# NUC123AN_v1 register map
File version: 1.0
NUC123AN_v1 SVD file
Registers are 32-bit, read-write, reset 0x0 unless marked. A register's access mark holds for its fields unless they carry their own. Offsets are from the block's base; lines under a group give offsets from that group; [hi:lo] are bit positions; {n}, {i} and the like mark numbered series; 'fields as' and 'values as' point back to an identical list; <NAME> marks a mode.

## Memory map
0x40004000 WDT size 0x8 — WDT Register Map
0x40004100 WWDT size 0x10 — WWDT Register Map
0x40010000 TMR01 blocks up to offset 0x3C — TIMER Register Map
0x40020000 I2C0 blocks up to offset 0x44 — I2C Register Map
0x40030000 SPI0 blocks up to offset 0x48 — SPI Register Map
0x40034000 SPI1 blocks up to offset 0x48 — SPI Register Map
0x40040000 PWMA blocks up to offset 0xD4 — PWM Register Map
0x40050000 UART0 size 0x34 — UART Register Map
0x40060000 USB blocks up to offset 0x580 — USB Register Map
0x400E0000 ADC blocks up to offset 0x44 — ADC Register Map
0x40100000 PS2 size 0x20 — PS2 Register Map
0x40110000 TMR23 blocks up to offset 0x3C — TIMER Register Map
0x40120000 I2C1 blocks up to offset 0x44 — I2C Register Map
0x40130000 SPI2 blocks up to offset 0x48 — SPI Register Map
0x40150000 UART1 size 0x34 — UART Register Map
0x401A0000 I2S size 0x18 — I2S Register Map
0x50000000 GCR blocks up to offset 0x104 — GCR Register Map
0x50000200 CLK blocks up to offset 0x30 — CLK Register Map
0x50000300 INT size 0x88 — INT Register Map
0x50004000 GP blocks up to offset 0x350 — GP Register Map
0x50008000 PDMA_ch0 blocks up to offset 0x84 — PDMA Register Map
0x50008100 PDMA_ch1 blocks up to offset 0x84 — PDMA Register Map
0x50008200 PDMA_ch2 blocks up to offset 0x84 — PDMA Register Map
0x50008300 PDMA_ch3 blocks up to offset 0x84 — PDMA Register Map
0x50008400 PDMA_ch4 blocks up to offset 0x84 — PDMA Register Map
0x50008500 PDMA_ch5 blocks up to offset 0x84 — PDMA Register Map
0x50008E00 CRC blocks up to offset 0x8C — PDMA Register Map
0x50008F00 DMA_GCR size 0x14 — PDMA Register Map
0x5000C000 FMC size 0x1C — FMC Register Map
0xE000E000 SCS blocks up to offset 0xD24 — SCS Register Map

## FMC — FMC Register Map
Base 0x5000C000
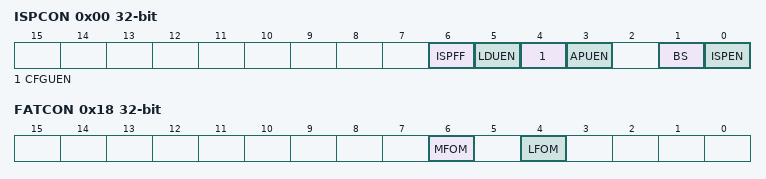
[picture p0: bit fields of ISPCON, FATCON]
0x00 ISPCON — ISP Control Register
  [6] ISPFF — ISP Fail Flag (Write-protection Bit). This bit is set by hardware when a triggered ISP meets any of the following conditions: (1) APROM writes to itself if APUEN is set to 0. (2) LDROM writes to itself if LDUEN is set to 0. (3) CONFIG is erased/programmed if CFGUEN is set to 0. (4) Destination address is illegal, such as over an available range. Write 1 to clear.
  [5] LDUEN — LDROM Update Enable (Write-protection Bit). LDROM update enable bit.
    0=LDROM cannot be updated; 1=LDROM can be updated
  [4] CFGUEN — Enable Config-bits Update by ISP (Write-protection Bit)
    0=ISP Disabled to update config-bits; 1=ISP Enabled to update config-bits
  [3] APUEN — APROM Update Enable (Write-protection Bit)
    0=APROM cannot be updated when the chip runs in APROM; 1=APROM can be updated when the chip runs in APROM
  [1] BS — Boot Select (Write-protection Bit). Set/clear this bit to select next booting from LDROM/APROM, respectively. This bit also functions as chip booting status flag, which can be used to check where chip booted from. This bit is initiated with the inversed value of CBS in Config0 after any reset is happened except CPU reset (RSTS_CPU is 1) or system reset (RSTS_SYS) is happened
    0=Boot from APROM; 1=Boot from LDROM
  [0] ISPEN — ISP Enable (Write-protection Bit). ISP function enable bit. Set this bit to enable ISP function.
    0=ISP function Disabled; 1=ISP function Enabled
0x04 ISPADR — ISP Address Register
  [31:0] ISPADR — ISP Address. The NuMicro( NUC123 Series is equipped with an embedded flash, and it supports word program only. ISPADR[1:0] must be kept 00b for ISP operation.
0x08 ISPDAT — ISP Data Register
  [31:0] ISPDAT — ISP Data. Write data to this register before ISP program operation. Read data from this register after ISP read operation.
0x0C ISPCMD — ISP Command Register
  [5:0] ISPCMD — ISP Command
0x10 ISPTRG — ISP Trigger Control Register
  [0] ISPGO — ISP Start Trigger. Write 1 to start ISP operation and this bit will be cleared to 0 by hardware automatically when ISP operation is finished.
    0=ISP operation is finished; 1=ISP is progressed
0x14 DFBADR ro reset not defined — Data Flash Start Address
  [31:0] DFBADR — Data Flash Base Address. This register indicates data flash start address. It is a read only register. When DFVSEN is set to 0, the data flash is shared with APROM. The data flash size is defined by user configuration and the content of this register is loaded from Config1. When DFVSEN is set to 1, the data flash size is fixed as 4K and the start address can be read from this register is fixed at 0x0001_F000.
0x18 FATCON — Flash Access Time Control Register
  [6] MFOM — Middle Frequency Optimization Mode (Write-protection Bit). When chip operation frequency is lower than 50 MHz, chip can work more efficiently by setting this bit to 1
    0=Middle Frequency Optimization mode Disabled; 1=Middle Frequency Optimization mode Enabled
  [4] LFOM — Low Frequency Optimization Mode (Write-protection Bit). When chip operation frequency is lower than 25 MHz, chip can work more efficiently by setting this bit to 1
    0=Low Frequency Optimization mode Disabled; 1=Low Frequency Optimization mode Enabled
